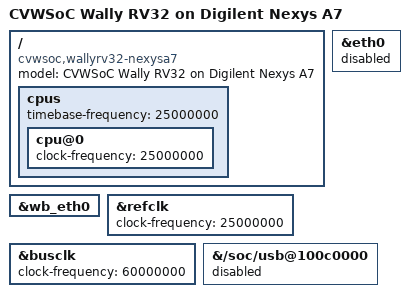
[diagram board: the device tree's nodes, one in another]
/dts-v1/;

/include/ "cvwsoc-cpu-wallyrv32.dtsi"
/include/ "cvwsoc.dtsi"
/include/ "cvwsoc-board-nexysa7.dtsi"

/ {
  model = "CVWSoC Wally RV32 on Digilent Nexys A7";
  compatible = "cvwsoc,wallyrv32-nexysa7", "cvwsoc,cvwsoc";

  cpus {
    timebase-frequency = <25000000>;
    cpu@0 {
      clock-frequency = <25000000>;
    };
  };


};

&eth0 { status = "disabled"; };
&wb_eth0 { status = "okay"; };

&refclk { clock-frequency = <25000000>; };
&busclk { clock-frequency = <60000000>; };

// Disabled until it fits
&{/soc/usb@100c0000} { status = "disabled"; };
